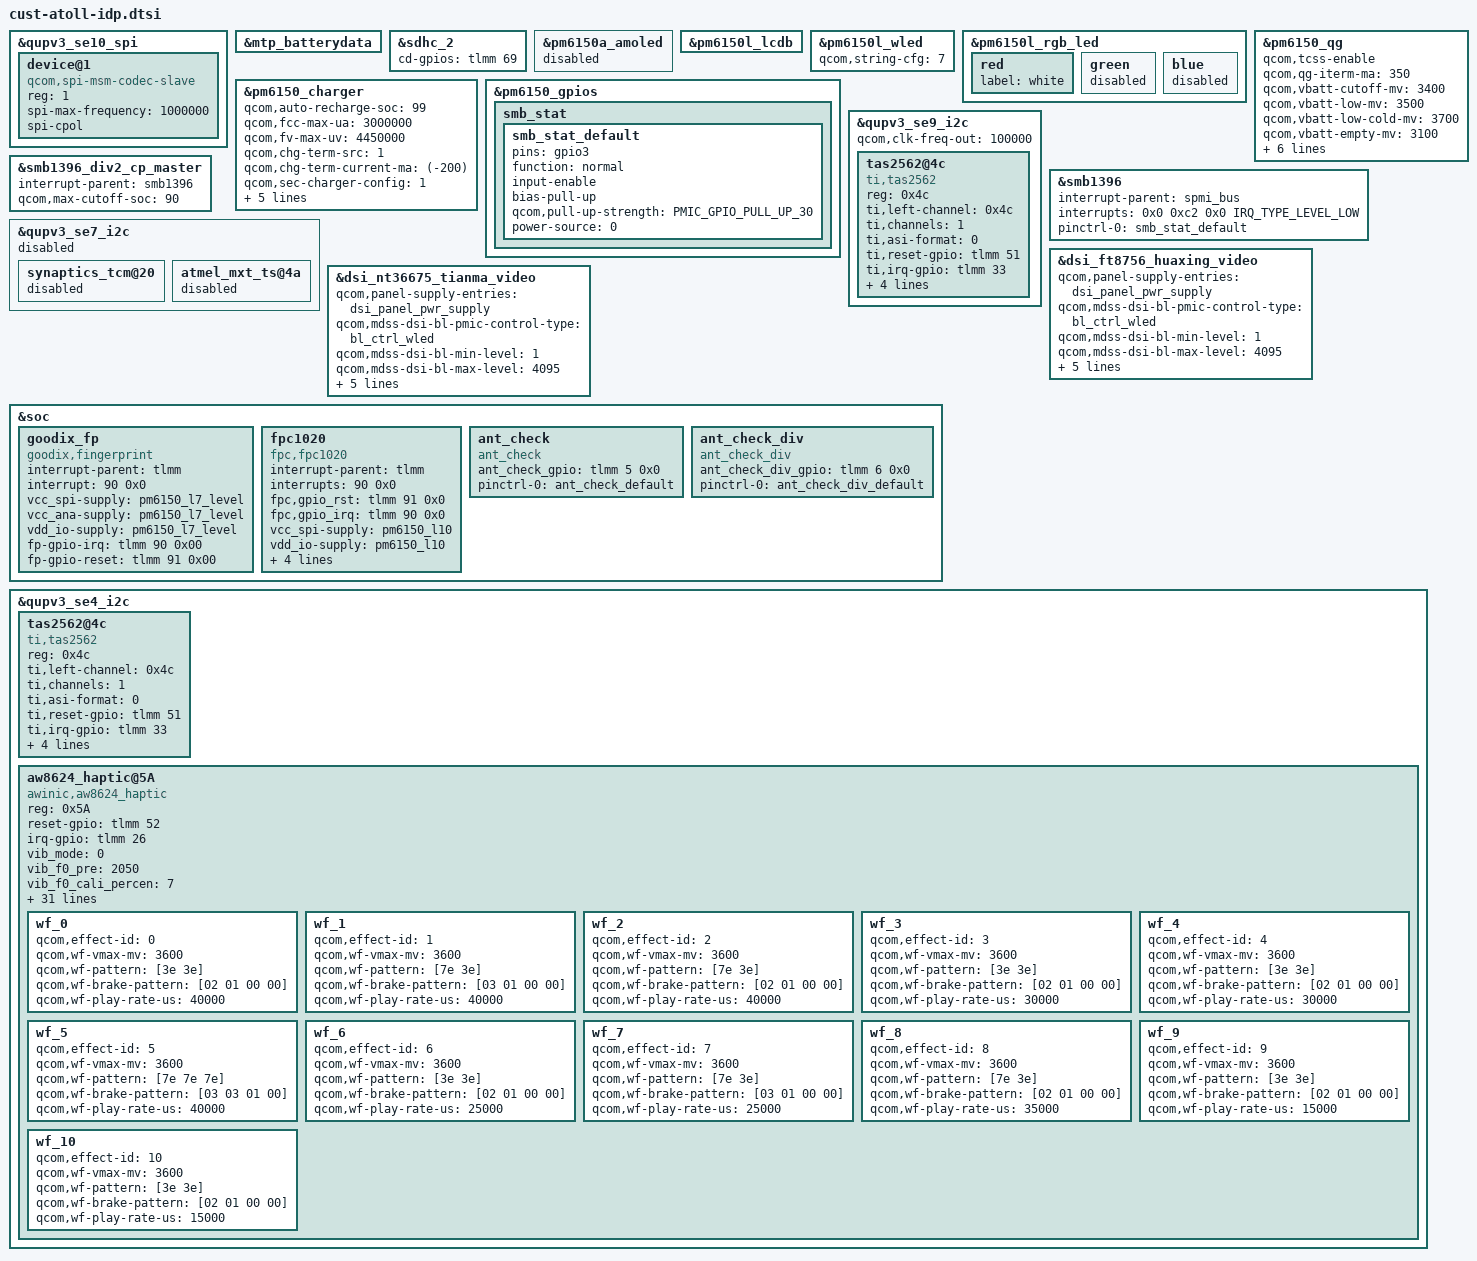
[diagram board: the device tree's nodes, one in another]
#include "touchscreen.dtsi"

&qupv3_se10_spi {
	status = "ok";

	device@1 {
		compatible = "qcom,spi-msm-codec-slave";
		#address-cells = <1>;
		#size-cells = <1>;
		reg = <1>; /* Chip select 0 */
		spi-max-frequency = <1000000>;
		spi-cpol;
	};
};

&mtp_batterydata {
	#include "qg-batterydata-sunwoda_5020mAh.dtsi"
	#include "qg-batterydata-atl_5020mAh.dtsi"
	#include "qg-batterydata-unknown_5020mAh.dtsi"
	#include "batterydata-J6B-nvt-5020mah.dtsi"
	#include "batterydata-J6B-sunwoda-5020mah.dtsi"
};

&sdhc_2 {
	cd-gpios = <&tlmm 69 0>;
};

&pm6150a_amoled {
	status = "disabled";
};

&pm6150l_lcdb {
	status = "ok";
};

&pm6150l_wled {
	status = "ok";
	qcom,string-cfg = <7>;
};

&pm6150l_rgb_led {
	red {
		label = "white";
	};

	green {
		status = "disabled";
	};

	blue {
		status = "disabled";
	};
};

&pm6150_qg {
	qcom,tcss-enable;
	qcom,qg-iterm-ma = <350>;
	qcom,vbatt-cutoff-mv = <3400>;
	qcom,vbatt-low-mv = <3500>;
	qcom,vbatt-low-cold-mv = <3700>;
	qcom,vbatt-empty-mv = <3100>;
	qcom,vbatt-empty-cold-mv = <3100>;
	qcom,s3-entry-ibat-ua = <25000>;
	qcom,s3-exit-ibat-ua = <45000>;
	qcom,s3-entry-fifo-length = <2>;
	qcom,qg-vadc = <&pm6150_vadc>;
	qcom,qg-ext-sns;
};

&pm6150_charger {
	qcom,auto-recharge-soc = <99>;
	qcom,fcc-max-ua = <3000000>;
	qcom,fv-max-uv = <4450000>;
	qcom,chg-term-src = <1>;
	qcom,chg-term-current-ma = <(-200)>;
	qcom,sec-charger-config = <1>;
	qcom,thermal-mitigation = <3000000 2500000 2000000 1500000 1000000 500000>;
	qcom,en-qc3-with-cp;
	qcom,disable-suspend-on-collapse;
	qcom,reg-dump-enable;
};

&pm6150_gpios {
	smb_stat {
	smb_stat_default: smb_stat_default {
			pins = "gpio3";
			function = "normal";
			input-enable;
			bias-pull-up;
			qcom,pull-up-strength = <PMIC_GPIO_PULL_UP_30>;
			power-source = <0>;
		};
	};
};

&qupv3_se9_i2c {
	status = "ok";
	qcom,clk-freq-out = <100000>;
	#include "smb1398.dtsi"
};

&smb1396 {
	status = "ok";
	interrupt-parent = <&spmi_bus>;
	interrupts = <0x0 0xc2 0x0 IRQ_TYPE_LEVEL_LOW>;
	pinctrl-names = "default";
	pinctrl-0 = <&smb_stat_default>;
};

&smb1396_div2_cp_master {
	status = "ok";
	interrupt-parent = <&smb1396>;
	qcom,max-cutoff-soc = <90>;
};

&qupv3_se7_i2c {
	status = "disabled";

	synaptics_tcm@20 {
		status = "disabled";
	};

	atmel_mxt_ts@4a {
		status = "disabled";
	};
};

&dsi_ft8756_huaxing_video {
	qcom,panel-supply-entries = <&dsi_panel_pwr_supply>;
	qcom,mdss-dsi-bl-pmic-control-type = "bl_ctrl_wled";
	qcom,mdss-dsi-bl-min-level = <1>;
	qcom,mdss-dsi-bl-max-level = <4095>;
	qcom,mdss-brightness-max-level = <4095>;
	qcom,mdss-dsi-bl-default-level = <1072>;
	qcom,platform-te-gpio = <&tlmm 10 0>;
	qcom,platform-reset-gpio = <&pm6150l_gpios 3 0>;
	qcom,dsi-display-active;
};

&dsi_nt36675_tianma_video {
	qcom,panel-supply-entries = <&dsi_panel_pwr_supply>;
	qcom,mdss-dsi-bl-pmic-control-type = "bl_ctrl_wled";
	qcom,mdss-dsi-bl-min-level = <1>;
	qcom,mdss-dsi-bl-max-level = <4095>;
	qcom,mdss-brightness-max-level = <4095>;
	qcom,mdss-dsi-bl-default-level = <1072>;
	qcom,platform-te-gpio = <&tlmm 10 0>;
	qcom,platform-reset-gpio = <&pm6150l_gpios 3 0>;
	qcom,dsi-display-active;
};

&soc {
	goodix_fp {
		compatible = "goodix,fingerprint";
		interrupt-parent = <&tlmm>;
		interrupt = <90 0x0>;
		vcc_spi-supply = <&pm6150_l7_level>;
		vcc_ana-supply = <&pm6150_l7_level>;
		vdd_io-supply = <&pm6150_l7_level>;
		fp-gpio-irq = <&tlmm 90 0x00>;
		fp-gpio-reset = <&tlmm 91 0x00>;
		status = "okay";
	};

	fpc1020 {
		status = "ok";
		compatible = "fpc,fpc1020";
		interrupt-parent = <&tlmm>;
		interrupts = <90 0x0>;
		fpc,gpio_rst    = <&tlmm 91 0x0>;
		fpc,gpio_irq    = <&tlmm 90 0x0>;
		vcc_spi-supply  = <&pm6150_l10>;
		vdd_io-supply   = <&pm6150_l10>;
		vdd_ana-supply  = <&pm6150_l10>;

		pinctrl-names = "fpc1020_reset_reset",
			"fpc1020_reset_active",
			"fpc1020_irq_active";

		pinctrl-0 = <&msm_gpio_91>;
		pinctrl-1 = <&msm_gpio_91_output_high>;
		pinctrl-2 = <&msm_gpio_90>;
	};

	ant_check {
		compatible = "ant_check";
		ant_check_gpio = <&tlmm 5 0x0>;
		pinctrl-names = "default";
		pinctrl-0 = <&ant_check_default>;
	};

	ant_check_div {
		compatible = "ant_check_div";
		ant_check_div_gpio = <&tlmm 6 0x0>;
		pinctrl-names = "default";
		pinctrl-0 = <&ant_check_div_default>;
	};
};

&qupv3_se9_i2c {
	status = "ok";
	qcom,clk-freq-out = <100000>;
	tas2562@4c {
		#sound-dai-cells = <0>;
		compatible = "ti,tas2562";
		reg = <0x4c>;
		ti,left-channel = <0x4c>; /* addr */
		//ti,right-channel = <0x4d>;
		ti,channels = <1>; /* channel number */
		ti,asi-format = <0>; /* 0, i2S; 1, DSP;  */
		ti,reset-gpio = <&tlmm 51 0>;
		//ti,reset-gpio2 = <&gpio1 16 0>;
		ti,irq-gpio = <&tlmm 33 0>;
		//ti,irq-gpio2 = <&gpio1 14 0>;
		ti,left-slot = <0>; /* <left slot number> */
		ti,right-slot = <1>; /* <right slot number> */
		ti,imon-slot-no = <0>; /* <current sense slot number> */
		ti,vmon-slot-no = <2>; /* <current voltage slot number> */
		status = "ok";
	};
};

&qupv3_se4_i2c {
	status = "ok";
	tas2562@4c {
		#sound-dai-cells = <0>;
		compatible = "ti,tas2562";
		reg = <0x4c>;
		ti,left-channel = <0x4c>; /* addr */
		//ti,right-channel = <0x4d>;
		ti,channels = <1>; /* channel number */
		ti,asi-format = <0>; /* 0, i2S; 1, DSP;  */
		ti,reset-gpio = <&tlmm 51 0>;
		//ti,reset-gpio2 = <&gpio1 16 0>;
		ti,irq-gpio = <&tlmm 33 0>;
		//ti,irq-gpio2 = <&gpio1 14 0>;
		ti,left-slot = <0>; /* <left slot number> */
		ti,right-slot = <1>; /* <right slot number> */
		ti,imon-slot-no = <0>; /* <current sense slot number> */
		ti,vmon-slot-no = <2>; /* <current voltage slot number> */
		status = "ok";
	};
};

&qupv3_se4_i2c {
	status = "ok";
	aw8624_haptic@5A {
		status = "ok";
		compatible = "awinic,aw8624_haptic", "ti,drv2624";
		reg = <0x5A>;
		reset-gpio = <&tlmm 52 0>;
		irq-gpio = <&tlmm 26 0>;
		vib_mode = <0>; /* 0: RAM mode 1:CONT mode*/
		vib_f0_pre = < 2050 >;
		vib_f0_cali_percen = < 7 >;
		vib_cont_drv_lev = < 100 >;
		vib_cont_drv_lvl_ov = < 105 >;
		vib_cont_td = < 0xF06C >;
		vib_cont_zc_thr = < 0x08F8 >;
		vib_cont_num_brk = < 3 >;
		vib_f0_coeff = < 260 >; /*Don't modify it*/
		vib_f0_trace_parameter = < 9 3 1 31 >;
		vib_bemf_config = < 0x10 0x08 0x23 0xf8 >;
		vib_sw_brake = < 0x2c >;
		vib_tset = < 0x11 >;
		vib_func_parameter1 = < 1 >;
		vib_r_spare = < 0x68 >;
		vib_effect_id_boundary = < 10 >;
		vib_gain_flag = < 1 >;
		vib_effect_max = < 170 >;
		vib_trig_config = < 0 1 0 1 2
				0 1 0 1 2
				0 1 0 1 2 >;
		vib_bst_vol_default = < 0x1b >;
		vib_bst_vol_ram = < 0x1b >;
		vib_bst_vol_rtp = < 0x16 >;
		vib_rtp_time = < 20 20 20 20 20 20 20 20 20000 15000
				 15000 20000 25000 15000 30000 25000 20000 20000 20000 20000
				 20000 20000 20000 20000 20000 20000 20000 20000 20000 20000
				 20000 20000 20000 20000 20000 20000 20000 20000 20000 20000
				 20000 20000 20000 20000 20000 20000 20000 20000 20000 20000
				 20000 20000 20000 20000 20000 20000 20000 20000 20000 20000
				 20000 20000 20000 20000 20000 20000 20000 20000 20000 20000
				 20000 20000 20000 20000 20000 20000 20000 20000 20000 20000
				 20000 20000 20000 20000 20000 20000 20000 20000 20000 20000
				 20000 20000 20000 20000 20000 20000 20000 20000 20000 20000
				 20000 20000 20000 20000 20000 20000 20000 20000 20000 20000
				 20000 20000 20000 20000 20000 20000 20000 20000 20000 20000
				 20000 20000 20000 20000 20000 20000 20000 20000 20000 20000
				 20000 20000 20000 20000 20000 20000 20000 20000 20000 20000
				 20000 20000 20000 20000 20000 20000 20000 20000 20000 20000
				 20000 20000 20000 20000 20000 20000 20000 20000 20000 20000
				 20000 20000 20000 20000 20000 20000 20000 20000 20000 20000
				 20000 20000 20000 20000 20000 >;
		pinctrl-names = "aw8624_reset_reset","aw8624_reset_active","aw8624_interrupt_active";
		pinctrl-0 = <&msm_gpio_52>;
		pinctrl-1 = <&msm_gpio_52_output_high>;
		pinctrl-2 = <&msm_gpio_26>;

		ti,reset-gpio = <&tlmm 52 0>;
		ti,irq-gpio = <&tlmm 26 0>;
		ti,smart-loop = <0>; /* 0-closeloop, 1-openloop*/
		ti,actuator = <1>; /* 0-ERM, 1-LRA */
		ti,rated-voltage = <2500>; /*1800mv*/
		ti,odclamp-voltage = <4000>; /*3000mv*/
		ti,lra-frequency = <175>; /* DON'T Care if ERM */
		wf_0 {
			/*CLICK*/
			qcom,effect-id = <0>;
			qcom,wf-vmax-mv = <3600>;
			qcom,wf-pattern = [3e 3e];
			qcom,wf-brake-pattern = [02 01 00 00];
			qcom,wf-play-rate-us = <40000>;
		};
		wf_1 {
			/*DOUBLE CLICK*/
			qcom,effect-id = <1>;
			qcom,wf-vmax-mv = <3600>;
			qcom,wf-pattern = [7e 3e];
			qcom,wf-brake-pattern = [03 01 00 00];
			qcom,wf-play-rate-us = <40000>;
		};
		wf_2 {
			/*TICK*/
			qcom,effect-id = <2>;
			qcom,wf-vmax-mv = <3600>;
			qcom,wf-pattern = [7e 3e];
			qcom,wf-brake-pattern = [02 01 00 00];
			qcom,wf-play-rate-us = <40000>;
		};
		wf_3 {
			/*THUD*/
			qcom,effect-id = <3>;
			qcom,wf-vmax-mv = <3600>;
			qcom,wf-pattern = [3e 3e];
			qcom,wf-brake-pattern = [02 01 00 00];
			qcom,wf-play-rate-us = <30000>;
		};
		wf_4 {
			/*POP*/
			qcom,effect-id = <4>;
			qcom,wf-vmax-mv = <3600>;
			qcom,wf-pattern = [3e 3e];
			qcom,wf-brake-pattern = [02 01 00 00];
			qcom,wf-play-rate-us = <30000>;
		};
		wf_5 {
			/*HEAVY CLICK*/
			qcom,effect-id = <5>;
			qcom,wf-vmax-mv = <3600>;
			qcom,wf-pattern = [7e 7e 7e];
			qcom,wf-brake-pattern = [03 03 01 00];
			qcom,wf-play-rate-us = <40000>;
		};
		wf_6 {
			/*CLICK*/
			qcom,effect-id = <6>;
			qcom,wf-vmax-mv = <3600>;
			qcom,wf-pattern = [3e 3e];
			qcom,wf-brake-pattern = [02 01 00 00];
			qcom,wf-play-rate-us = <25000>;
		};
		wf_7 {
			/*DOUBLE CLICK*/
			qcom,effect-id = <7>;
			qcom,wf-vmax-mv = <3600>;
			qcom,wf-pattern = [7e 3e];
			qcom,wf-brake-pattern = [03 01 00 00];
			qcom,wf-play-rate-us = <25000>;
		};
		wf_8 {
			/*TICK*/
			qcom,effect-id = <8>;
			qcom,wf-vmax-mv = <3600>;
			qcom,wf-pattern = [7e 3e];
			qcom,wf-brake-pattern = [02 01 00 00];
			qcom,wf-play-rate-us = <35000>;
		};
		wf_9 {
			/*THUD*/
			qcom,effect-id = <9>;
			qcom,wf-vmax-mv = <3600>;
			qcom,wf-pattern = [3e 3e];
			qcom,wf-brake-pattern = [02 01 00 00];
			qcom,wf-play-rate-us = <15000>;
		};
		wf_10 {
			/*POP*/
			qcom,effect-id = <10>;
			qcom,wf-vmax-mv = <3600>;
			qcom,wf-pattern = [3e 3e];
			qcom,wf-brake-pattern = [02 01 00 00];
			qcom,wf-play-rate-us = <15000>;
		};
	};
};
